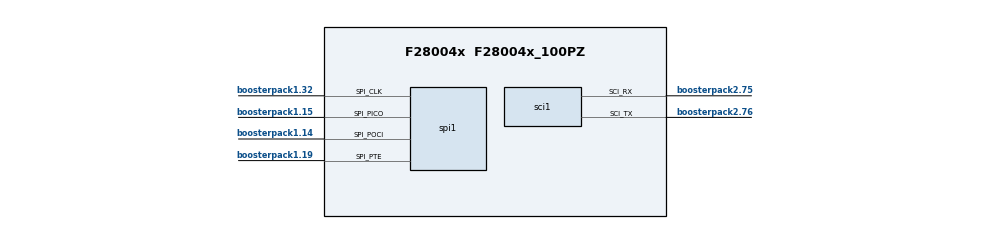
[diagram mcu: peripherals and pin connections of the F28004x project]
/**
 * @cliArgs --board "/boards/LAUNCHXL_F280049C" --device "F28004x" --part "F28004x_100PZ" --package "F28004x_100PZ" --context "system" --product "C2000WARE@26.00.00.00"
 * @versions {"tool":"1.27.1+4634"}
 */

/**
 * Import the modules used in this configuration.
 */
const device_support = scripting.addModule("/driverlib/device_support.js");
const sci            = scripting.addModule("/driverlib/sci.js", {}, false);
const sci1           = sci.addInstance();
const spi            = scripting.addModule("/driverlib/spi.js", {}, false);
const spi1           = spi.addInstance();
const sysctl         = scripting.addModule("/driverlib/sysctl.js");
const CMD            = scripting.addModule("/utilities/cmd_tool/cmd_syscfg/source/CMD");
const CMD1           = CMD.addInstance();
const CMD2           = CMD.addInstance();

/**
 * Write custom configuration values to the imported modules.
 */
sci1.$name                 = "mySCI0";
sci1.sci.$assign           = "SCIA";
sci1.sci.sci_rxPin.$assign = "boosterpack2.75";
sci1.sci.sci_txPin.$assign = "boosterpack2.76";
sci1.rxQual.$name          = "myGPIOQUAL4";
sci1.txQual.$name          = "myGPIOQUAL5";

spi1.$name                   = "mySPI0";
spi1.useFifo                 = false;
spi1.useInterrupts           = false;
spi1.dataWidth               = "8";
spi1.emulationMode           = "SPI_EMULATION_FREE_RUN";
spi1.spi.$assign             = "SPIA";
spi1.spi.spi_picoPin.$assign = "boosterpack1.15";
spi1.spi.spi_pociPin.$assign = "boosterpack1.14";
spi1.spi.spi_clkPin.$assign  = "boosterpack1.32";
spi1.spi.spi_ptePin.$assign  = "boosterpack1.19";
spi1.picoQual.$name          = "myGPIOQUAL0";
spi1.pociQual.$name          = "myGPIOQUAL1";
spi1.clkQual.$name           = "myGPIOQUAL2";
spi1.pteQual.$name           = "myGPIOQUAL3";

CMD1.$name                    = "generic_ram_lnk";
CMD1.sectionMemory_text       = ["RAMGS0","RAMLS4","RAMLS5","RAMLS6","RAMLS7"];
CMD1.sectionMemory_ramfunc    = ["RAMM0"];
CMD1.sectionMemory_cinit      = ["RAMM0"];
CMD1.sectionMemory_stack      = ["RAMM1"];
CMD1.sectionMemory_init_array = ["RAMM0"];
CMD1.sectionMemory_bss        = ["RAMLS4"];
CMD1.sectionMemory_const      = ["RAMLS4"];
CMD1.sectionMemory_data       = ["RAMLS4"];
CMD1.sectionMemory_switch     = ["RAMM0"];
CMD1.sectionMemory_sysmem     = ["RAMLS4"];
CMD1.sectionRun_ramfunc       = ["RAMLS4"];

CMD2.$name                               = "generic_flash_lnk";
CMD2.sectionAlignEnable_ramfunc          = true;
CMD2.sectionAlignEnable_text             = true;
CMD2.sectionAlignEnable_binit            = true;
CMD2.sectionAlignEnable_cinit            = true;
CMD2.sectionAlignEnable_switch           = true;
CMD2.sectionAlignEnable_init_array       = true;
CMD2.sectionAlignEnable_const            = true;
CMD2.sectionAlignEnable_ovly             = true;
CMD2.sectionMemory_codestart             = "0x080000";
CMD2.sectionMemory_stack                 = ["RAMM1"];
CMD2.sectionMemory_ramfunc               = ["FLASH_BANK0_SEC1"];
CMD2.sectionMemory_text                  = ["FLASH_BANK0_SEC2","FLASH_BANK0_SEC3","FLASH_BANK0_SEC4"];
CMD2.sectionMemory_binit                 = ["FLASH_BANK0_SEC1"];
CMD2.sectionMemory_cinit                 = ["FLASH_BANK0_SEC1"];
CMD2.sectionMemory_switch                = ["FLASH_BANK0_SEC1"];
CMD2.sectionMemory_bss                   = ["RAMLS5"];
CMD2.sectionMemory_data                  = ["RAMLS5"];
CMD2.sectionMemory_sysmem                = ["RAMLS5"];
CMD2.sectionRunFromDifferentAddr_ramfunc = true;
CMD2.sectionBinit_ramfunc                = false;
CMD2.sectionMemory_init_array            = ["FLASH_BANK0_SEC1"];
CMD2.sectionMemory_const                 = ["FLASH_BANK0_SEC4"];
CMD2.sectionMemory_ovly                  = ["FLASH_BANK0_SEC1"];
